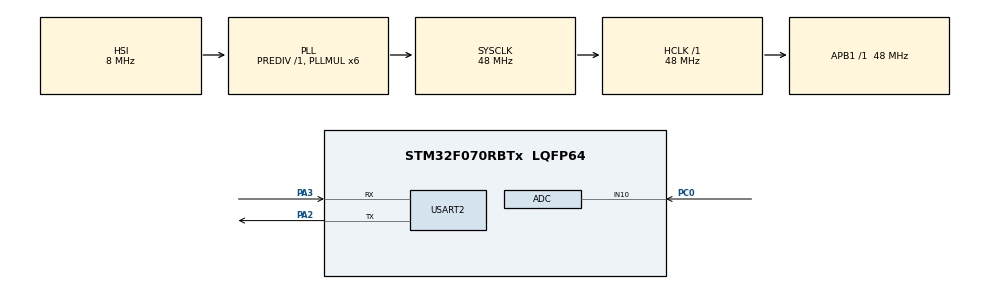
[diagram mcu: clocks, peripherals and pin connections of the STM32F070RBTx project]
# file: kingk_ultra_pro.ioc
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ADC.ContinuousConvMode=ENABLE
Dma.ADC.0.Direction=DMA_PERIPH_TO_MEMORY
Dma.ADC.0.Instance=DMA1_Channel1
Dma.ADC.0.MemDataAlignment=DMA_MDATAALIGN_WORD
Dma.ADC.0.MemInc=DMA_MINC_ENABLE
Dma.ADC.0.Mode=DMA_CIRCULAR
Dma.ADC.0.PeriphDataAlignment=DMA_PDATAALIGN_WORD
Dma.ADC.0.PeriphInc=DMA_PINC_DISABLE
Dma.ADC.0.Priority=DMA_PRIORITY_LOW
Dma.Request0=ADC
Mcu.Family=STM32F0
Mcu.Name=STM32F070RBTx
Mcu.Package=LQFP64
NVIC.ADC1_IRQn=true\:1\:0\:true\:false\:true\:true\:true\:true
NVIC.DMA1_Channel1_IRQn=true\:0\:0\:false\:false\:true\:false\:true\:true
NVIC.TIM16_IRQn=true\:0\:0\:true\:false\:true\:true\:true\:true
PA2.Mode=Asynchronous
PA2.Signal=USART2_TX
PA3.Mode=Asynchronous
PA3.Signal=USART2_RX
PC0.Mode=IN10
PC0.Signal=ADC_IN10
ProjectManager.HeapSize=0x200
ProjectManager.StackSize=0x400
ProjectManager.TargetToolchain=MDK-ARM V5.32
RCC.AHBFreq_Value=48000000
RCC.APB1Freq_Value=48000000
RCC.APB1TimFreq_Value=48000000
RCC.HCLKFreq_Value=48000000
RCC.PLLMUL=RCC_PLL_MUL6
RCC.SYSCLKFreq_VALUE=48000000
RCC.SYSCLKSource=RCC_SYSCLKSOURCE_PLLCLK
TIM16.Period=1000-1
TIM16.Prescaler=48000-1
USART2.VirtualMode-Asynchronous=VM_ASYNC
VP_TIM16_VS_ClockSourceINT.Mode=Enable_Timer
board=custom

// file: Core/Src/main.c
/* USER CODE BEGIN Header */
/**
  ******************************************************************************
  * @file           : main.c
  * @brief          : Main program body
  ******************************************************************************
  * @attention
  *
  * Copyright (c) 2023 STMicroelectronics.
  * All rights reserved.
  *
  * This software is licensed under terms that can be found in the LICENSE file
  * in the root directory of this software component.
  * If no LICENSE file comes with this software, it is provided AS-IS.
  *
  ******************************************************************************
  */
/* USER CODE END Header */
#include "main.h"

/* USER CODE BEGIN Includes */
#include "stdio.h"
#include "string.h"
/* USER CODE END Includes */

ADC_HandleTypeDef hadc;
DMA_HandleTypeDef hdma_adc;

TIM_HandleTypeDef htim16;

UART_HandleTypeDef huart2;

/* USER CODE BEGIN PV */

uint16_t buffer;
int count = 0, maxCount = -1, prevCount = 0;
uint8_t val = 100;
uint8_t oneSecondFlag = 0;
char max_buffer[1000];

/* USER CODE END PV */

void SystemClock_Config(void);
static void MX_GPIO_Init(void);
static void MX_DMA_Init(void);
static void MX_ADC_Init(void);
static void MX_TIM16_Init(void);
static void MX_USART2_UART_Init(void);

/* USER CODE BEGIN 0 */

void HAL_TIM_PeriodElapsedCallback(TIM_HandleTypeDef *htim)
{

	prevCount = count;
  if (count > maxCount)
  {
    maxCount = count;
  }

	if(count !=  0) oneSecondFlag=1;

}

void HAL_ADC_ConvCpltCallback(ADC_HandleTypeDef* hadc)
{
	count++;
	char buffer_str[5];
  sprintf(buffer_str, "%u ", buffer); // Assuming 'buffer' is a uint16_t
	strcat(max_buffer, buffer_str);
}
/* USER CODE END 0 */

int main(void)
{

  /* MCU Configuration--------------------------------------------------------*/

  /* Reset of all peripherals, Initializes the Flash interface and the Systick. */
  HAL_Init();

  /* Configure the system clock */
  SystemClock_Config();

  /* Initialize all configured peripherals */
  MX_GPIO_Init();
  MX_DMA_Init();
  MX_ADC_Init();
  MX_TIM16_Init();
  MX_USART2_UART_Init();
  /* USER CODE BEGIN 2 */
	HAL_TIM_Base_Start_IT(&htim16);
	HAL_ADC_Start_IT(&hadc);
  /* USER CODE END 2 */

  /* Infinite loop */
while (1)
{

    /* USER CODE BEGIN 3 */
	// Transmit the data via USART
	if (oneSecondFlag==1){
		  count = 0;
		  oneSecondFlag=0;
      HAL_UART_Transmit(&huart2, (uint8_t*)max_buffer, strlen(max_buffer), 1000);
      memset(max_buffer, '\0', sizeof(max_buffer));
	}
}

  /* USER CODE END 3 */
}

void SystemClock_Config(void)
{
  RCC_OscInitTypeDef RCC_OscInitStruct = {0};
  RCC_ClkInitTypeDef RCC_ClkInitStruct = {0};

  /** Initializes the RCC Oscillators according to the specified parameters
  * in the RCC_OscInitTypeDef structure.
  */
  RCC_OscInitStruct.OscillatorType = RCC_OSCILLATORTYPE_HSI|RCC_OSCILLATORTYPE_HSI14;
  RCC_OscInitStruct.HSIState = RCC_HSI_ON;
  RCC_OscInitStruct.HSI14State = RCC_HSI14_ON;
  RCC_OscInitStruct.HSICalibrationValue = RCC_HSICALIBRATION_DEFAULT;
  RCC_OscInitStruct.HSI14CalibrationValue = 16;
  RCC_OscInitStruct.PLL.PLLState = RCC_PLL_ON;
  RCC_OscInitStruct.PLL.PLLSource = RCC_PLLSOURCE_HSI;
  RCC_OscInitStruct.PLL.PLLMUL = RCC_PLL_MUL6;
  RCC_OscInitStruct.PLL.PREDIV = RCC_PREDIV_DIV1;
  if (HAL_RCC_OscConfig(&RCC_OscInitStruct) != HAL_OK)
  {
    Error_Handler();
  }

  /** Initializes the CPU, AHB and APB buses clocks
  */
  RCC_ClkInitStruct.ClockType = RCC_CLOCKTYPE_HCLK|RCC_CLOCKTYPE_SYSCLK
                              |RCC_CLOCKTYPE_PCLK1;
  RCC_ClkInitStruct.SYSCLKSource = RCC_SYSCLKSOURCE_PLLCLK;
  RCC_ClkInitStruct.AHBCLKDivider = RCC_SYSCLK_DIV1;
  RCC_ClkInitStruct.APB1CLKDivider = RCC_HCLK_DIV1;

  if (HAL_RCC_ClockConfig(&RCC_ClkInitStruct, FLASH_LATENCY_1) != HAL_OK)
  {
    Error_Handler();
  }
}

static void MX_ADC_Init(void)
{

  ADC_ChannelConfTypeDef sConfig = {0};

  /** Configure the global features of the ADC (Clock, Resolution, Data Alignment and number of conversion)
  */
  hadc.Instance = ADC1;
  hadc.Init.ClockPrescaler = ADC_CLOCK_ASYNC_DIV1;
  hadc.Init.Resolution = ADC_RESOLUTION_12B;
  hadc.Init.DataAlign = ADC_DATAALIGN_RIGHT;
  hadc.Init.ScanConvMode = ADC_SCAN_DIRECTION_FORWARD;
  hadc.Init.EOCSelection = ADC_EOC_SINGLE_CONV;
  hadc.Init.LowPowerAutoWait = DISABLE;
  hadc.Init.LowPowerAutoPowerOff = DISABLE;
  hadc.Init.ContinuousConvMode = ENABLE;
  hadc.Init.DiscontinuousConvMode = DISABLE;
  hadc.Init.ExternalTrigConv = ADC_SOFTWARE_START;
  hadc.Init.ExternalTrigConvEdge = ADC_EXTERNALTRIGCONVEDGE_NONE;
  hadc.Init.DMAContinuousRequests = DISABLE;
  hadc.Init.Overrun = ADC_OVR_DATA_PRESERVED;
  if (HAL_ADC_Init(&hadc) != HAL_OK)
  {
    Error_Handler();
  }

  /** Configure for the selected ADC regular channel to be converted.
  */
  sConfig.Channel = ADC_CHANNEL_10;
  sConfig.Rank = ADC_RANK_CHANNEL_NUMBER;
  sConfig.SamplingTime = ADC_SAMPLETIME_1CYCLE_5;
  if (HAL_ADC_ConfigChannel(&hadc, &sConfig) != HAL_OK)
  {
    Error_Handler();
  }

}

static void MX_TIM16_Init(void)
{

  htim16.Instance = TIM16;
  htim16.Init.Prescaler = 48000-1;
  htim16.Init.CounterMode = TIM_COUNTERMODE_UP;
  htim16.Init.Period = 1000-1;
  htim16.Init.ClockDivision = TIM_CLOCKDIVISION_DIV1;
  htim16.Init.RepetitionCounter = 0;
  htim16.Init.AutoReloadPreload = TIM_AUTORELOAD_PRELOAD_DISABLE;
  if (HAL_TIM_Base_Init(&htim16) != HAL_OK)
  {
    Error_Handler();
  }

}

static void MX_USART2_UART_Init(void)
{

  huart2.Instance = USART2;
  huart2.Init.BaudRate = 38400;
  huart2.Init.WordLength = UART_WORDLENGTH_8B;
  huart2.Init.StopBits = UART_STOPBITS_1;
  huart2.Init.Parity = UART_PARITY_NONE;
  huart2.Init.Mode = UART_MODE_TX_RX;
  huart2.Init.HwFlowCtl = UART_HWCONTROL_NONE;
  huart2.Init.OverSampling = UART_OVERSAMPLING_16;
  huart2.Init.OneBitSampling = UART_ONE_BIT_SAMPLE_DISABLE;
  huart2.AdvancedInit.AdvFeatureInit = UART_ADVFEATURE_NO_INIT;
  if (HAL_UART_Init(&huart2) != HAL_OK)
  {
    Error_Handler();
  }

}

static void MX_DMA_Init(void)
{

  /* DMA controller clock enable */
  __HAL_RCC_DMA1_CLK_ENABLE();

  /* DMA interrupt init */
  /* DMA1_Channel1_IRQn interrupt configuration */
  HAL_NVIC_SetPriority(DMA1_Channel1_IRQn, 0, 0);
  HAL_NVIC_EnableIRQ(DMA1_Channel1_IRQn);

}

static void MX_GPIO_Init(void)
{

  /* GPIO Ports Clock Enable */
  __HAL_RCC_GPIOC_CLK_ENABLE();
  __HAL_RCC_GPIOA_CLK_ENABLE();

}

void Error_Handler(void)
{
  __disable_irq();
  while (1)
  {
  }
}
